AUTOSAR XML (schema 00049)
package /Application/DltConfig
  dlt log channel to process mapping DltLogChannelToProcessMapping_KATECH_TO_KATECH: dlt-log-channel=KATECH, process=KATECH
package /Application/Executable
  executable KATECH: category=APPLICATION_LEVEL, logging-behavior=USES-LOGGING, reporting-behavior=REPORTS-EXECUTION-STATE, version=1.0.0
    root sw component prototype AA: application-type=KATECH
package /Application/Manifest
  service instance to port prototype mapping KATECH_AA_RPortBCMWiper: port-prototype=AA.RPortBCMWiper, service-instance=EEVP_KATECH_Consumer_BCM_WiperWash
  service instance to port prototype mapping KATECH_AA_RPortRearCurtain: port-prototype=AA.RPortRearCurtain, service-instance=EEVP_KATECH_Consumer_RearCurtain
  service instance to port prototype mapping KATECH_AA_RPortRoa: port-prototype=AA.RPortRoa, service-instance=EEVP_KATECH_Consumer_SoaRoa
package /Application/Process
  process KATECH: executable=KATECH, state-dependent-startup-config{execution-dependency=CM.Running, function-group-state=MachineFG.Startup, resource-group=DefaultResourceGroup, startup-config=KATECH}
    process state machine KATECH: type=ProcessState
package /Application/StartupConfig
  startup config set EEVP_KATECH_StartupConfig
    startup config KATECH: scheduling-policy=SCHED_OTHER, scheduling-priority=0
package /Application/SwComponent
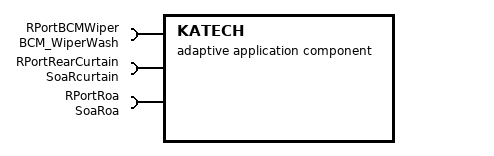
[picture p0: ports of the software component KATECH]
  adaptive application sw component type KATECH
    require port RPortBCMWiper: required-interface=BCM_WiperWash
    require port RPortRearCurtain: required-interface=SoaRcurtain
    require port RPortRoa: required-interface=SoaRoa
